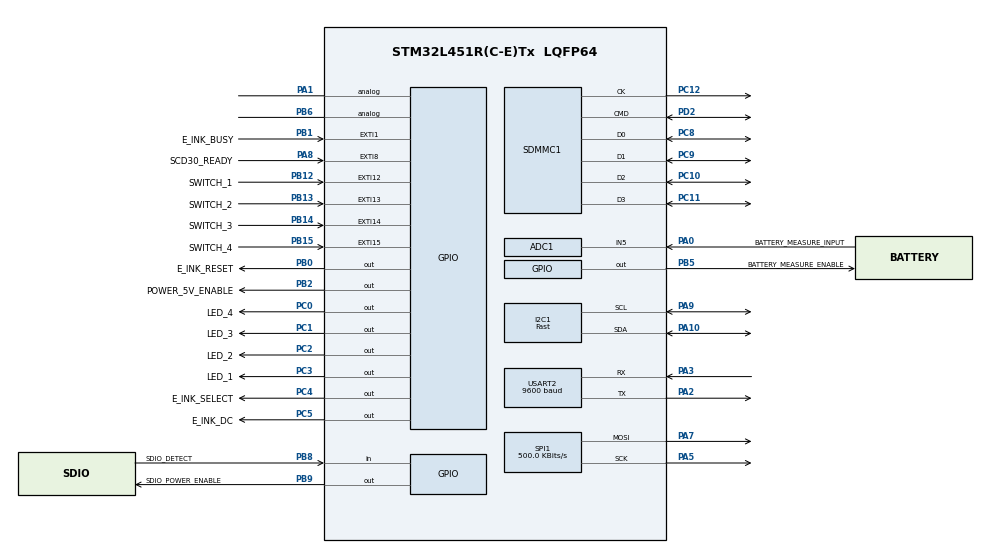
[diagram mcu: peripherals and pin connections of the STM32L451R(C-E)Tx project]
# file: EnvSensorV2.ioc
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ADC1.Channel-0\#ChannelRegularConversion=ADC_CHANNEL_5
ADC1.Channel-16\#ChannelRegularConversion=ADC_CHANNEL_5
ADC1.Channel-17\#ChannelRegularConversion=ADC_CHANNEL_5
ADC1.Channel-18\#ChannelRegularConversion=ADC_CHANNEL_5
ADC1.Channel-19\#ChannelRegularConversion=ADC_CHANNEL_5
ADC1.Channel-20\#ChannelRegularConversion=ADC_CHANNEL_5
ADC1.Channel-21\#ChannelRegularConversion=ADC_CHANNEL_5
ADC1.Channel-22\#ChannelRegularConversion=ADC_CHANNEL_5
ADC1.Channel-23\#ChannelRegularConversion=ADC_CHANNEL_5
ADC1.Channel-24\#ChannelRegularConversion=ADC_CHANNEL_5
ADC1.Channel-25\#ChannelRegularConversion=ADC_CHANNEL_5
ADC1.Channel-26\#ChannelRegularConversion=ADC_CHANNEL_5
ADC1.Channel-27\#ChannelRegularConversion=ADC_CHANNEL_5
ADC1.Channel-28\#ChannelRegularConversion=ADC_CHANNEL_5
ADC1.Channel-29\#ChannelRegularConversion=ADC_CHANNEL_5
ADC1.Channel-30\#ChannelRegularConversion=ADC_CHANNEL_5
ADC1.ClockPrescaler=ADC_CLOCK_ASYNC_DIV16
ADC1.NbrOfConversion=16
ADC1.NbrOfConversionFlag=1
ADC1.OffsetNumber-0\#ChannelRegularConversion=ADC_OFFSET_NONE
ADC1.OffsetNumber-16\#ChannelRegularConversion=ADC_OFFSET_NONE
ADC1.OffsetNumber-17\#ChannelRegularConversion=ADC_OFFSET_NONE
ADC1.OffsetNumber-18\#ChannelRegularConversion=ADC_OFFSET_NONE
ADC1.OffsetNumber-19\#ChannelRegularConversion=ADC_OFFSET_NONE
ADC1.OffsetNumber-20\#ChannelRegularConversion=ADC_OFFSET_NONE
ADC1.OffsetNumber-21\#ChannelRegularConversion=ADC_OFFSET_NONE
ADC1.OffsetNumber-22\#ChannelRegularConversion=ADC_OFFSET_NONE
ADC1.OffsetNumber-23\#ChannelRegularConversion=ADC_OFFSET_NONE
ADC1.OffsetNumber-24\#ChannelRegularConversion=ADC_OFFSET_NONE
ADC1.OffsetNumber-25\#ChannelRegularConversion=ADC_OFFSET_NONE
ADC1.OffsetNumber-26\#ChannelRegularConversion=ADC_OFFSET_NONE
ADC1.OffsetNumber-27\#ChannelRegularConversion=ADC_OFFSET_NONE
ADC1.OffsetNumber-28\#ChannelRegularConversion=ADC_OFFSET_NONE
ADC1.OffsetNumber-29\#ChannelRegularConversion=ADC_OFFSET_NONE
ADC1.OffsetNumber-30\#ChannelRegularConversion=ADC_OFFSET_NONE
ADC1.OversamplingMode=DISABLE
ADC1.Rank-0\#ChannelRegularConversion=1
ADC1.Rank-16\#ChannelRegularConversion=2
ADC1.Rank-17\#ChannelRegularConversion=3
ADC1.Rank-18\#ChannelRegularConversion=4
ADC1.Rank-19\#ChannelRegularConversion=5
ADC1.Rank-20\#ChannelRegularConversion=6
ADC1.Rank-21\#ChannelRegularConversion=7
ADC1.Rank-22\#ChannelRegularConversion=8
ADC1.Rank-23\#ChannelRegularConversion=9
ADC1.Rank-24\#ChannelRegularConversion=10
ADC1.Rank-25\#ChannelRegularConversion=11
ADC1.Rank-26\#ChannelRegularConversion=12
ADC1.Rank-27\#ChannelRegularConversion=13
ADC1.Rank-28\#ChannelRegularConversion=14
ADC1.Rank-29\#ChannelRegularConversion=15
ADC1.Rank-30\#ChannelRegularConversion=16
ADC1.SamplingTime-0\#ChannelRegularConversion=ADC_SAMPLETIME_640CYCLES_5
ADC1.SamplingTime-16\#ChannelRegularConversion=ADC_SAMPLETIME_2CYCLES_5
ADC1.SamplingTime-17\#ChannelRegularConversion=ADC_SAMPLETIME_2CYCLES_5
ADC1.SamplingTime-18\#ChannelRegularConversion=ADC_SAMPLETIME_2CYCLES_5
ADC1.SamplingTime-19\#ChannelRegularConversion=ADC_SAMPLETIME_2CYCLES_5
ADC1.SamplingTime-20\#ChannelRegularConversion=ADC_SAMPLETIME_2CYCLES_5
ADC1.SamplingTime-21\#ChannelRegularConversion=ADC_SAMPLETIME_2CYCLES_5
ADC1.SamplingTime-22\#ChannelRegularConversion=ADC_SAMPLETIME_2CYCLES_5
ADC1.SamplingTime-23\#ChannelRegularConversion=ADC_SAMPLETIME_2CYCLES_5
ADC1.SamplingTime-24\#ChannelRegularConversion=ADC_SAMPLETIME_2CYCLES_5
ADC1.SamplingTime-25\#ChannelRegularConversion=ADC_SAMPLETIME_2CYCLES_5
ADC1.SamplingTime-26\#ChannelRegularConversion=ADC_SAMPLETIME_2CYCLES_5
ADC1.SamplingTime-27\#ChannelRegularConversion=ADC_SAMPLETIME_2CYCLES_5
ADC1.SamplingTime-28\#ChannelRegularConversion=ADC_SAMPLETIME_2CYCLES_5
ADC1.SamplingTime-29\#ChannelRegularConversion=ADC_SAMPLETIME_2CYCLES_5
ADC1.SamplingTime-30\#ChannelRegularConversion=ADC_SAMPLETIME_2CYCLES_5
ADC1.master=1
FATFS.BSP.number=1
FATFS._CODE_PAGE=852
FATFS._MAX_SS=4096
FATFS._USE_LFN=3
FATFS0.BSP.STBoard=false
FATFS0.BSP.api=Unknown
FATFS0.BSP.instance=PB8
FATFS0.BSP.ip=GPIO
FATFS0.BSP.mode=Input
FATFS0.BSP.name=Detect_SDIO
FATFS0.BSP.solution=PB8
FREERTOS.HEAP_NUMBER=3
FREERTOS.INCLUDE_xTaskGetHandle=0
FREERTOS.Mutexes01=i2c1Mutex,Static,i2c1MutexControlBlock
FREERTOS.Queues01=debugLogQueue,16,30,1,Static,debugLogQueueBuffer,debugLogQueueControlBlock;sensorReadoutsQueue,6,ReadoutMessage_t,0,Static,sensorReadoutsQueueBuffer,sensorReadoutsQueueControlBlock;displayCommandsQueue,6,DisplayCommandMessage_t,0,Static,displayCommandsQueueBuffer,displayCommandsQueueControlBlock
FREERTOS.Tasks01=defaultTask,24,1024,StartDefaultTask,Default,NULL,Static,defaultTaskBuffer,defaultTaskControlBlock
FREERTOS.configCHECK_FOR_STACK_OVERFLOW=0
FREERTOS.configTOTAL_HEAP_SIZE=50000
FREERTOS.configUSE_NEWLIB_REENTRANT=1
I2C1.I2C_Speed_Mode=I2C_Fast
I2C1.Timing=0x00000004
Mcu.Family=STM32L4
Mcu.Name=STM32L451R(C-E)Tx
Mcu.Package=LQFP64
NVIC.EXTI15_10_IRQn=true\:5\:0\:false\:false\:true\:true\:true\:true\:true
NVIC.EXTI1_IRQn=true\:5\:0\:false\:false\:true\:true\:true\:true\:true
NVIC.EXTI9_5_IRQn=true\:5\:0\:true\:false\:true\:true\:true\:true\:true
NVIC.PriorityGroup=NVIC_PRIORITYGROUP_4
NVIC.SDMMC1_IRQn=true\:5\:0\:false\:false\:true\:true\:true\:true\:true
NVIC.TIM6_DAC_IRQn=true\:15\:0\:false\:false\:true\:false\:false\:true\:true
NVIC.TimeBase=TIM6_DAC_IRQn
NVIC.TimeBaseIP=TIM6
NVIC.USART2_IRQn=true\:5\:0\:false\:false\:true\:true\:true\:true\:true
PA0.GPIO_Label=BATTERY_MEASURE_INPUT
PA0.Signal=ADCx_IN5
PA1.Signal=GPIO_Analog
PA10.Mode=I2C
PA10.Signal=I2C1_SDA
PA13\ (JTMS/SWDIO).Mode=Trace_Asynchronous_SW
PA13\ (JTMS/SWDIO).Signal=SYS_JTMS-SWDIO
PA14\ (JTCK/SWCLK).Mode=Trace_Asynchronous_SW
PA14\ (JTCK/SWCLK).Signal=SYS_JTCK-SWCLK
PA2.Mode=Asynchronous
PA2.Signal=USART2_TX
PA3.Mode=Asynchronous
PA3.Signal=USART2_RX
PA5.Mode=TX_Only_Simplex_Unidirect_Master
PA5.Signal=SPI1_SCK
PA7.Mode=TX_Only_Simplex_Unidirect_Master
PA7.Signal=SPI1_MOSI
PA8.GPIO_Label=SCD30_READY
PA8.GPIO_PuPd=GPIO_NOPULL
PA8.Signal=GPXTI8
PA9.Mode=I2C
PA9.Signal=I2C1_SCL
PB0.GPIO_Label=E_INK_RESET
PB0.Signal=GPIO_Output
PB1.GPIO_Label=E_INK_BUSY
PB1.Signal=GPXTI1
PB12.GPIO_Label=SWITCH_1
PB12.Signal=GPXTI12
PB13.GPIO_Label=SWITCH_2
PB13.Signal=GPXTI13
PB14.GPIO_Label=SWITCH_3
PB14.Signal=GPXTI14
PB15.GPIO_Label=SWITCH_4
PB15.Signal=GPXTI15
PB2.GPIO_Label=POWER_5V_ENABLE
PB2.PinState=GPIO_PIN_SET
PB2.Signal=GPIO_Output
PB3\ (JTDO/TRACESWO).Mode=Trace_Asynchronous_SW
PB3\ (JTDO/TRACESWO).Signal=SYS_JTDO-SWO
PB5.GPIO_Label=BATTERY_MEASURE_ENABLE
PB5.Signal=GPIO_Output
PB6.Signal=GPIO_Analog
PB8.GPIO_Label=SDIO_DETECT
PB8.Signal=GPIO_Input
PB9.GPIO_Label=SDIO_POWER_ENABLE
PB9.Signal=GPIO_Output
PC0.GPIO_Label=LED_4
PC0.Signal=GPIO_Output
PC1.GPIO_Label=LED_3
PC1.Signal=GPIO_Output
PC10.Mode=SD_4_bits_Wide_bus
PC10.Signal=SDMMC1_D2
PC11.Mode=SD_4_bits_Wide_bus
PC11.Signal=SDMMC1_D3
PC12.Mode=SD_4_bits_Wide_bus
PC12.Signal=SDMMC1_CK
PC2.GPIO_Label=LED_2
PC2.Signal=GPIO_Output
PC3.GPIO_Label=LED_1
PC3.Signal=GPIO_Output
PC4.GPIO_Label=E_INK_SELECT
PC4.Signal=GPIO_Output
PC5.GPIO_Label=E_INK_DC
PC5.GPIO_Speed=GPIO_SPEED_FREQ_HIGH
PC5.Signal=GPIO_Output
PC8.Mode=SD_4_bits_Wide_bus
PC8.Signal=SDMMC1_D0
PC9.Mode=SD_4_bits_Wide_bus
PC9.Signal=SDMMC1_D1
PD2.Mode=SD_4_bits_Wide_bus
PD2.Signal=SDMMC1_CMD
PH0-OSC_IN\ (PH0).Mode=HSE-External-Oscillator
PH0-OSC_IN\ (PH0).Signal=RCC_OSC_IN
PH1-OSC_OUT\ (PH1).Mode=HSE-External-Oscillator
PH1-OSC_OUT\ (PH1).Signal=RCC_OSC_OUT
ProjectManager.HeapSize=0x200
ProjectManager.StackSize=0x400
ProjectManager.TargetToolchain=STM32CubeIDE
RCC.ADCFreq_Value=64000000
RCC.HSE_VALUE=16000000
RCC.HSI48_VALUE=48000000
RCC.HSI_VALUE=16000000
RCC.LSE_VALUE=32768
RCC.MSI_VALUE=4000000
RCC.PLLSAI1Q=RCC_PLLQ_DIV4
RCC.PLLSourceVirtual=RCC_PLLSOURCE_HSE
RCC.VCOOutputFreq_Value=128000000
SH.ADCx_IN5.0=ADC1_IN5,IN5-Single-Ended
SPI1.BaudRatePrescaler=SPI_BAUDRATEPRESCALER_8
SPI1.CalculateBaudRate=500.0 KBits/s
SPI1.DataSize=SPI_DATASIZE_8BIT
SPI1.Direction=SPI_DIRECTION_2LINES
SPI1.Mode=SPI_MODE_MASTER
SPI1.VirtualType=VM_MASTER
USART2.BaudRate=9600
USART2.VirtualMode-Asynchronous=VM_ASYNC
VP_CRC_VS_CRC.Mode=CRC_Activate
VP_FATFS_VS_SDIO.Mode=SDIO
VP_FREERTOS_VS_CMSIS_V2.Mode=CMSIS_V2
VP_RTC_VS_RTC_Activate.Mode=RTC_Enabled
VP_SYS_VS_tim6.Mode=TIM6
board=custom

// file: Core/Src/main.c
/* USER CODE BEGIN Header */
/**
  ******************************************************************************
  * @file           : main.c
  * @brief          : Main program body
  ******************************************************************************
  * @attention
  *
  * <h2><center>&copy; Copyright (c) 2022 STMicroelectronics.
  * All rights reserved.</center></h2>
  *
  * This software component is licensed by ST under BSD 3-Clause license,
  * the "License"; You may not use this file except in compliance with the
  * License. You may obtain a copy of the License at:
  *                        opensource.org/licenses/BSD-3-Clause
  *
  ******************************************************************************
  */
/* USER CODE END Header */
#include "main.h"
#include "cmsis_os.h"
#include "fatfs.h"
#include "app_touchgfx.h"

/* USER CODE BEGIN Includes */
#include <EnvSensorV2.hpp>
#include <Readouts/SensorMessages.hpp>
#include <Display/DisplayCommandMessage.hpp>
/* USER CODE END Includes */

typedef StaticTask_t osStaticThreadDef_t;
typedef StaticQueue_t osStaticMessageQDef_t;
typedef StaticSemaphore_t osStaticMutexDef_t;

ADC_HandleTypeDef hadc1;

CRC_HandleTypeDef hcrc;

I2C_HandleTypeDef hi2c1;

RTC_HandleTypeDef hrtc;

SD_HandleTypeDef hsd1;

SPI_HandleTypeDef hspi1;

UART_HandleTypeDef huart2;

/* Definitions for defaultTask */
osThreadId_t defaultTaskHandle;
uint32_t defaultTaskBuffer[ 1024 ];
osStaticThreadDef_t defaultTaskControlBlock;
const osThreadAttr_t defaultTask_attributes = {
  .name = "defaultTask",
  .cb_mem = &defaultTaskControlBlock,
  .cb_size = sizeof(defaultTaskControlBlock),
  .stack_mem = &defaultTaskBuffer[0],
  .stack_size = sizeof(defaultTaskBuffer),
  .priority = (osPriority_t) osPriorityNormal,
};
/* Definitions for debugLogQueue */
osMessageQueueId_t debugLogQueueHandle;
uint8_t debugLogQueueBuffer[ 16 * 30 ];
osStaticMessageQDef_t debugLogQueueControlBlock;
const osMessageQueueAttr_t debugLogQueue_attributes = {
  .name = "debugLogQueue",
  .cb_mem = &debugLogQueueControlBlock,
  .cb_size = sizeof(debugLogQueueControlBlock),
  .mq_mem = &debugLogQueueBuffer,
  .mq_size = sizeof(debugLogQueueBuffer)
};
/* Definitions for sensorReadoutsQueue */
osMessageQueueId_t sensorReadoutsQueueHandle;
uint8_t sensorReadoutsQueueBuffer[ 6 * sizeof( ReadoutMessage_t ) ];
osStaticMessageQDef_t sensorReadoutsQueueControlBlock;
const osMessageQueueAttr_t sensorReadoutsQueue_attributes = {
  .name = "sensorReadoutsQueue",
  .cb_mem = &sensorReadoutsQueueControlBlock,
  .cb_size = sizeof(sensorReadoutsQueueControlBlock),
  .mq_mem = &sensorReadoutsQueueBuffer,
  .mq_size = sizeof(sensorReadoutsQueueBuffer)
};
/* Definitions for displayCommandsQueue */
osMessageQueueId_t displayCommandsQueueHandle;
uint8_t displayCommandsQueueBuffer[ 6 * sizeof( DisplayCommandMessage_t ) ];
osStaticMessageQDef_t displayCommandsQueueControlBlock;
const osMessageQueueAttr_t displayCommandsQueue_attributes = {
  .name = "displayCommandsQueue",
  .cb_mem = &displayCommandsQueueControlBlock,
  .cb_size = sizeof(displayCommandsQueueControlBlock),
  .mq_mem = &displayCommandsQueueBuffer,
  .mq_size = sizeof(displayCommandsQueueBuffer)
};
/* Definitions for i2c1Mutex */
osMutexId_t i2c1MutexHandle;
osStaticMutexDef_t i2c1MutexControlBlock;
const osMutexAttr_t i2c1Mutex_attributes = {
  .name = "i2c1Mutex",
  .cb_mem = &i2c1MutexControlBlock,
  .cb_size = sizeof(i2c1MutexControlBlock),
};

void SystemClock_Config(void);
void PeriphCommonClock_Config(void);
static void MX_GPIO_Init(void);
static void MX_I2C1_Init(void);
static void MX_USART2_UART_Init(void);
static void MX_SPI1_Init(void);
static void MX_CRC_Init(void);
static void MX_ADC1_Init(void);
static void MX_RTC_Init(void);
static void MX_SDMMC1_SD_Init(void);
void StartDefaultTask(void *argument);

int main(void)
{

  /* MCU Configuration--------------------------------------------------------*/

  /* Reset of all peripherals, Initializes the Flash interface and the Systick. */
  HAL_Init();

  /* Configure the system clock */
  SystemClock_Config();

/* Configure the peripherals common clocks */
  PeriphCommonClock_Config();

  /* Initialize all configured peripherals */
  MX_GPIO_Init();
  MX_I2C1_Init();
  MX_USART2_UART_Init();
  MX_SPI1_Init();
  MX_CRC_Init();
  MX_ADC1_Init();
  MX_RTC_Init();
  MX_SDMMC1_SD_Init();
  MX_FATFS_Init();
  MX_TouchGFX_Init();
  /* Call PreOsInit function */
  MX_TouchGFX_PreOSInit();
  /* USER CODE BEGIN 2 */
  HAL_GPIO_WritePin(LED_2_GPIO_Port, LED_2_Pin, GPIO_PIN_SET);
  /* USER CODE END 2 */

  /* Init scheduler */
  osKernelInitialize();
  /* Create the mutex(es) */
  /* creation of i2c1Mutex */
  i2c1MutexHandle = osMutexNew(&i2c1Mutex_attributes);

  /* Create the queue(s) */
  /* creation of debugLogQueue */
  debugLogQueueHandle = osMessageQueueNew (16, 30, &debugLogQueue_attributes);

  /* creation of sensorReadoutsQueue */
  sensorReadoutsQueueHandle = osMessageQueueNew (6, sizeof(ReadoutMessage_t), &sensorReadoutsQueue_attributes);

  /* creation of displayCommandsQueue */
  displayCommandsQueueHandle = osMessageQueueNew (6, sizeof(DisplayCommandMessage_t), &displayCommandsQueue_attributes);

  /* Create the thread(s) */
  /* creation of defaultTask */
  defaultTaskHandle = osThreadNew(StartDefaultTask, NULL, &defaultTask_attributes);

  /* USER CODE BEGIN RTOS_THREADS */
  EnvSensorV2_Init();
  /* add threads, ... */
  /* USER CODE END RTOS_THREADS */

  /* Start scheduler */
  osKernelStart();
  /* We should never get here as control is now taken by the scheduler */
  /* Infinite loop */
  while (1)
  {

    /* USER CODE BEGIN 3 */
	  HAL_GPIO_TogglePin(LED_2_GPIO_Port, LED_2_Pin);
	  HAL_Delay(250);
  }
  /* USER CODE END 3 */
}

void SystemClock_Config(void)
{
  RCC_OscInitTypeDef RCC_OscInitStruct = {0};
  RCC_ClkInitTypeDef RCC_ClkInitStruct = {0};

  /** Configure the main internal regulator output voltage
  */
  if (HAL_PWREx_ControlVoltageScaling(PWR_REGULATOR_VOLTAGE_SCALE1) != HAL_OK)
  {
    Error_Handler();
  }

  /** Initializes the RCC Oscillators according to the specified parameters
  * in the RCC_OscInitTypeDef structure.
  */
  RCC_OscInitStruct.OscillatorType = RCC_OSCILLATORTYPE_LSI|RCC_OSCILLATORTYPE_HSE
                              |RCC_OSCILLATORTYPE_MSI;
  RCC_OscInitStruct.HSEState = RCC_HSE_ON;
  RCC_OscInitStruct.LSIState = RCC_LSI_ON;
  RCC_OscInitStruct.MSIState = RCC_MSI_ON;
  RCC_OscInitStruct.MSICalibrationValue = 0;
  RCC_OscInitStruct.MSIClockRange = RCC_MSIRANGE_6;
  RCC_OscInitStruct.PLL.PLLState = RCC_PLL_NONE;
  if (HAL_RCC_OscConfig(&RCC_OscInitStruct) != HAL_OK)
  {
    Error_Handler();
  }

  /** Initializes the CPU, AHB and APB buses clocks
  */
  RCC_ClkInitStruct.ClockType = RCC_CLOCKTYPE_HCLK|RCC_CLOCKTYPE_SYSCLK
                              |RCC_CLOCKTYPE_PCLK1|RCC_CLOCKTYPE_PCLK2;
  RCC_ClkInitStruct.SYSCLKSource = RCC_SYSCLKSOURCE_MSI;
  RCC_ClkInitStruct.AHBCLKDivider = RCC_SYSCLK_DIV1;
  RCC_ClkInitStruct.APB1CLKDivider = RCC_HCLK_DIV1;
  RCC_ClkInitStruct.APB2CLKDivider = RCC_HCLK_DIV1;

  if (HAL_RCC_ClockConfig(&RCC_ClkInitStruct, FLASH_LATENCY_0) != HAL_OK)
  {
    Error_Handler();
  }
}

void PeriphCommonClock_Config(void)
{
  RCC_PeriphCLKInitTypeDef PeriphClkInit = {0};

  /** Initializes the peripherals clock
  */
  PeriphClkInit.PeriphClockSelection = RCC_PERIPHCLK_SDMMC1|RCC_PERIPHCLK_ADC;
  PeriphClkInit.AdcClockSelection = RCC_ADCCLKSOURCE_PLLSAI1;
  PeriphClkInit.Sdmmc1ClockSelection = RCC_SDMMC1CLKSOURCE_PLLSAI1;
  PeriphClkInit.PLLSAI1.PLLSAI1Source = RCC_PLLSOURCE_HSE;
  PeriphClkInit.PLLSAI1.PLLSAI1M = 1;
  PeriphClkInit.PLLSAI1.PLLSAI1N = 8;
  PeriphClkInit.PLLSAI1.PLLSAI1P = RCC_PLLP_DIV7;
  PeriphClkInit.PLLSAI1.PLLSAI1Q = RCC_PLLQ_DIV4;
  PeriphClkInit.PLLSAI1.PLLSAI1R = RCC_PLLR_DIV2;
  PeriphClkInit.PLLSAI1.PLLSAI1ClockOut = RCC_PLLSAI1_48M2CLK|RCC_PLLSAI1_ADC1CLK;
  if (HAL_RCCEx_PeriphCLKConfig(&PeriphClkInit) != HAL_OK)
  {
    Error_Handler();
  }
}

static void MX_ADC1_Init(void)
{

  ADC_ChannelConfTypeDef sConfig = {0};

  /** Common config
  */
  hadc1.Instance = ADC1;
  hadc1.Init.ClockPrescaler = ADC_CLOCK_ASYNC_DIV16;
  hadc1.Init.Resolution = ADC_RESOLUTION_12B;
  hadc1.Init.DataAlign = ADC_DATAALIGN_RIGHT;
  hadc1.Init.ScanConvMode = ADC_SCAN_ENABLE;
  hadc1.Init.EOCSelection = ADC_EOC_SINGLE_CONV;
  hadc1.Init.LowPowerAutoWait = DISABLE;
  hadc1.Init.ContinuousConvMode = DISABLE;
  hadc1.Init.NbrOfConversion = 16;
  hadc1.Init.DiscontinuousConvMode = DISABLE;
  hadc1.Init.ExternalTrigConv = ADC_SOFTWARE_START;
  hadc1.Init.ExternalTrigConvEdge = ADC_EXTERNALTRIGCONVEDGE_NONE;
  hadc1.Init.DMAContinuousRequests = DISABLE;
  hadc1.Init.Overrun = ADC_OVR_DATA_PRESERVED;
  hadc1.Init.OversamplingMode = DISABLE;
  hadc1.Init.DFSDMConfig = ADC_DFSDM_MODE_ENABLE;
  if (HAL_ADC_Init(&hadc1) != HAL_OK)
  {
    Error_Handler();
  }

  /** Configure Regular Channel
  */
  sConfig.Channel = ADC_CHANNEL_5;
  sConfig.Rank = ADC_REGULAR_RANK_1;
  sConfig.SamplingTime = ADC_SAMPLETIME_640CYCLES_5;
  sConfig.SingleDiff = ADC_SINGLE_ENDED;
  sConfig.OffsetNumber = ADC_OFFSET_NONE;
  sConfig.Offset = 0;
  if (HAL_ADC_ConfigChannel(&hadc1, &sConfig) != HAL_OK)
  {
    Error_Handler();
  }

  /** Configure Regular Channel
  */
  sConfig.Rank = ADC_REGULAR_RANK_2;
  sConfig.SamplingTime = ADC_SAMPLETIME_2CYCLES_5;
  if (HAL_ADC_ConfigChannel(&hadc1, &sConfig) != HAL_OK)
  {
    Error_Handler();
  }

  /** Configure Regular Channel
  */
  sConfig.Rank = ADC_REGULAR_RANK_3;
  if (HAL_ADC_ConfigChannel(&hadc1, &sConfig) != HAL_OK)
  {
    Error_Handler();
  }

  /** Configure Regular Channel
  */
  sConfig.Rank = ADC_REGULAR_RANK_4;
  if (HAL_ADC_ConfigChannel(&hadc1, &sConfig) != HAL_OK)
  {
    Error_Handler();
  }

  /** Configure Regular Channel
  */
  sConfig.Rank = ADC_REGULAR_RANK_5;
  if (HAL_ADC_ConfigChannel(&hadc1, &sConfig) != HAL_OK)
  {
    Error_Handler();
  }

  /** Configure Regular Channel
  */
  sConfig.Rank = ADC_REGULAR_RANK_6;
  if (HAL_ADC_ConfigChannel(&hadc1, &sConfig) != HAL_OK)
  {
    Error_Handler();
  }

  /** Configure Regular Channel
  */
  sConfig.Rank = ADC_REGULAR_RANK_7;
  if (HAL_ADC_ConfigChannel(&hadc1, &sConfig) != HAL_OK)
  {
    Error_Handler();
  }

  /** Configure Regular Channel
  */
  sConfig.Rank = ADC_REGULAR_RANK_8;
  if (HAL_ADC_ConfigChannel(&hadc1, &sConfig) != HAL_OK)
  {
    Error_Handler();
  }

  /** Configure Regular Channel
  */
  sConfig.Rank = ADC_REGULAR_RANK_9;
  if (HAL_ADC_ConfigChannel(&hadc1, &sConfig) != HAL_OK)
  {
    Error_Handler();
  }

  /** Configure Regular Channel
  */
  sConfig.Rank = ADC_REGULAR_RANK_10;
  if (HAL_ADC_ConfigChannel(&hadc1, &sConfig) != HAL_OK)
  {
    Error_Handler();
  }

  /** Configure Regular Channel
  */
  sConfig.Rank = ADC_REGULAR_RANK_11;
  if (HAL_ADC_ConfigChannel(&hadc1, &sConfig) != HAL_OK)
  {
    Error_Handler();
  }

  /** Configure Regular Channel
  */
  sConfig.Rank = ADC_REGULAR_RANK_12;
  if (HAL_ADC_ConfigChannel(&hadc1, &sConfig) != HAL_OK)
  {
    Error_Handler();
  }

  /** Configure Regular Channel
  */
  sConfig.Rank = ADC_REGULAR_RANK_13;
  if (HAL_ADC_ConfigChannel(&hadc1, &sConfig) != HAL_OK)
  {
    Error_Handler();
  }

  /** Configure Regular Channel
  */
  sConfig.Rank = ADC_REGULAR_RANK_14;
  if (HAL_ADC_ConfigChannel(&hadc1, &sConfig) != HAL_OK)
  {
    Error_Handler();
  }

  /** Configure Regular Channel
  */
  sConfig.Rank = ADC_REGULAR_RANK_15;
  if (HAL_ADC_ConfigChannel(&hadc1, &sConfig) != HAL_OK)
  {
    Error_Handler();
  }

  /** Configure Regular Channel
  */
  sConfig.Rank = ADC_REGULAR_RANK_16;
  if (HAL_ADC_ConfigChannel(&hadc1, &sConfig) != HAL_OK)
  {
    Error_Handler();
  }

}

static void MX_CRC_Init(void)
{

  hcrc.Instance = CRC;
  hcrc.Init.DefaultPolynomialUse = DEFAULT_POLYNOMIAL_ENABLE;
  hcrc.Init.DefaultInitValueUse = DEFAULT_INIT_VALUE_ENABLE;
  hcrc.Init.InputDataInversionMode = CRC_INPUTDATA_INVERSION_NONE;
  hcrc.Init.OutputDataInversionMode = CRC_OUTPUTDATA_INVERSION_DISABLE;
  hcrc.InputDataFormat = CRC_INPUTDATA_FORMAT_BYTES;
  if (HAL_CRC_Init(&hcrc) != HAL_OK)
  {
    Error_Handler();
  }

}

static void MX_I2C1_Init(void)
{

  hi2c1.Instance = I2C1;
  hi2c1.Init.Timing = 0x00000004;
  hi2c1.Init.OwnAddress1 = 0;
  hi2c1.Init.AddressingMode = I2C_ADDRESSINGMODE_7BIT;
  hi2c1.Init.DualAddressMode = I2C_DUALADDRESS_DISABLE;
  hi2c1.Init.OwnAddress2 = 0;
  hi2c1.Init.OwnAddress2Masks = I2C_OA2_NOMASK;
  hi2c1.Init.GeneralCallMode = I2C_GENERALCALL_DISABLE;
  hi2c1.Init.NoStretchMode = I2C_NOSTRETCH_DISABLE;
  if (HAL_I2C_Init(&hi2c1) != HAL_OK)
  {
    Error_Handler();
  }

  /** Configure Analogue filter
  */
  if (HAL_I2CEx_ConfigAnalogFilter(&hi2c1, I2C_ANALOGFILTER_ENABLE) != HAL_OK)
  {
    Error_Handler();
  }

  /** Configure Digital filter
  */
  if (HAL_I2CEx_ConfigDigitalFilter(&hi2c1, 0) != HAL_OK)
  {
    Error_Handler();
  }

}

static void MX_RTC_Init(void)
{

  /** Initialize RTC Only
  */
  hrtc.Instance = RTC;
  hrtc.Init.HourFormat = RTC_HOURFORMAT_24;
  hrtc.Init.AsynchPrediv = 127;
  hrtc.Init.SynchPrediv = 255;
  hrtc.Init.OutPut = RTC_OUTPUT_DISABLE;
  hrtc.Init.OutPutRemap = RTC_OUTPUT_REMAP_NONE;
  hrtc.Init.OutPutPolarity = RTC_OUTPUT_POLARITY_HIGH;
  hrtc.Init.OutPutType = RTC_OUTPUT_TYPE_OPENDRAIN;
  if (HAL_RTC_Init(&hrtc) != HAL_OK)
  {
    Error_Handler();
  }

}

static void MX_SDMMC1_SD_Init(void)
{

  hsd1.Instance = SDMMC1;
  hsd1.Init.ClockEdge = SDMMC_CLOCK_EDGE_RISING;
  hsd1.Init.ClockBypass = SDMMC_CLOCK_BYPASS_DISABLE;
  hsd1.Init.ClockPowerSave = SDMMC_CLOCK_POWER_SAVE_DISABLE;
  hsd1.Init.BusWide = SDMMC_BUS_WIDE_4B;
  hsd1.Init.HardwareFlowControl = SDMMC_HARDWARE_FLOW_CONTROL_DISABLE;
  hsd1.Init.ClockDiv = 0;

}

static void MX_SPI1_Init(void)
{

  /* SPI1 parameter configuration*/
  hspi1.Instance = SPI1;
  hspi1.Init.Mode = SPI_MODE_MASTER;
  hspi1.Init.Direction = SPI_DIRECTION_2LINES;
  hspi1.Init.DataSize = SPI_DATASIZE_8BIT;
  hspi1.Init.CLKPolarity = SPI_POLARITY_LOW;
  hspi1.Init.CLKPhase = SPI_PHASE_1EDGE;
  hspi1.Init.NSS = SPI_NSS_SOFT;
  hspi1.Init.BaudRatePrescaler = SPI_BAUDRATEPRESCALER_8;
  hspi1.Init.FirstBit = SPI_FIRSTBIT_MSB;
  hspi1.Init.TIMode = SPI_TIMODE_DISABLE;
  hspi1.Init.CRCCalculation = SPI_CRCCALCULATION_DISABLE;
  hspi1.Init.CRCPolynomial = 7;
  hspi1.Init.CRCLength = SPI_CRC_LENGTH_DATASIZE;
  hspi1.Init.NSSPMode = SPI_NSS_PULSE_ENABLE;
  if (HAL_SPI_Init(&hspi1) != HAL_OK)
  {
    Error_Handler();
  }

}

static void MX_USART2_UART_Init(void)
{

  huart2.Instance = USART2;
  huart2.Init.BaudRate = 9600;
  huart2.Init.WordLength = UART_WORDLENGTH_8B;
  huart2.Init.StopBits = UART_STOPBITS_1;
  huart2.Init.Parity = UART_PARITY_NONE;
  huart2.Init.Mode = UART_MODE_TX_RX;
  huart2.Init.HwFlowCtl = UART_HWCONTROL_NONE;
  huart2.Init.OverSampling = UART_OVERSAMPLING_16;
  huart2.Init.OneBitSampling = UART_ONE_BIT_SAMPLE_DISABLE;
  huart2.AdvancedInit.AdvFeatureInit = UART_ADVFEATURE_NO_INIT;
  if (HAL_UART_Init(&huart2) != HAL_OK)
  {
    Error_Handler();
  }

}

static void MX_GPIO_Init(void)
{
  GPIO_InitTypeDef GPIO_InitStruct = {0};

  /* GPIO Ports Clock Enable */
  __HAL_RCC_GPIOH_CLK_ENABLE();
  __HAL_RCC_GPIOC_CLK_ENABLE();
  __HAL_RCC_GPIOA_CLK_ENABLE();
  __HAL_RCC_GPIOB_CLK_ENABLE();
  __HAL_RCC_GPIOD_CLK_ENABLE();

  /*Configure GPIO pin Output Level */
  HAL_GPIO_WritePin(GPIOC, LED_4_Pin|LED_3_Pin|LED_2_Pin|LED_1_Pin
                          |E_INK_SELECT_Pin|E_INK_DC_Pin, GPIO_PIN_RESET);

  /*Configure GPIO pin Output Level */
  HAL_GPIO_WritePin(GPIOB, E_INK_RESET_Pin|BATTERY_MEASURE_ENABLE_Pin|SDIO_POWER_ENABLE_Pin, GPIO_PIN_RESET);

  /*Configure GPIO pin Output Level */
  HAL_GPIO_WritePin(POWER_5V_ENABLE_GPIO_Port, POWER_5V_ENABLE_Pin, GPIO_PIN_SET);

  /*Configure GPIO pins : LED_4_Pin LED_3_Pin LED_2_Pin LED_1_Pin
                           E_INK_SELECT_Pin */
  GPIO_InitStruct.Pin = LED_4_Pin|LED_3_Pin|LED_2_Pin|LED_1_Pin
                          |E_INK_SELECT_Pin;
  GPIO_InitStruct.Mode = GPIO_MODE_OUTPUT_PP;
  GPIO_InitStruct.Pull = GPIO_NOPULL;
  GPIO_InitStruct.Speed = GPIO_SPEED_FREQ_LOW;
  HAL_GPIO_Init(GPIOC, &GPIO_InitStruct);

  /*Configure GPIO pin : PA1 */
  GPIO_InitStruct.Pin = GPIO_PIN_1;
  GPIO_InitStruct.Mode = GPIO_MODE_ANALOG;
  GPIO_InitStruct.Pull = GPIO_NOPULL;
  HAL_GPIO_Init(GPIOA, &GPIO_InitStruct);

  /*Configure GPIO pin : E_INK_DC_Pin */
  GPIO_InitStruct.Pin = E_INK_DC_Pin;
  GPIO_InitStruct.Mode = GPIO_MODE_OUTPUT_PP;
  GPIO_InitStruct.Pull = GPIO_NOPULL;
  GPIO_InitStruct.Speed = GPIO_SPEED_FREQ_HIGH;
  HAL_GPIO_Init(E_INK_DC_GPIO_Port, &GPIO_InitStruct);

  /*Configure GPIO pins : E_INK_RESET_Pin POWER_5V_ENABLE_Pin BATTERY_MEASURE_ENABLE_Pin SDIO_POWER_ENABLE_Pin */
  GPIO_InitStruct.Pin = E_INK_RESET_Pin|POWER_5V_ENABLE_Pin|BATTERY_MEASURE_ENABLE_Pin|SDIO_POWER_ENABLE_Pin;
  GPIO_InitStruct.Mode = GPIO_MODE_OUTPUT_PP;
  GPIO_InitStruct.Pull = GPIO_NOPULL;
  GPIO_InitStruct.Speed = GPIO_SPEED_FREQ_LOW;
  HAL_GPIO_Init(GPIOB, &GPIO_InitStruct);

  /*Configure GPIO pins : E_INK_BUSY_Pin SWITCH_1_Pin SWITCH_2_Pin SWITCH_3_Pin
                           SWITCH_4_Pin */
  GPIO_InitStruct.Pin = E_INK_BUSY_Pin|SWITCH_1_Pin|SWITCH_2_Pin|SWITCH_3_Pin
                          |SWITCH_4_Pin;
  GPIO_InitStruct.Mode = GPIO_MODE_IT_RISING;
  GPIO_InitStruct.Pull = GPIO_NOPULL;
  HAL_GPIO_Init(GPIOB, &GPIO_InitStruct);

  /*Configure GPIO pin : SCD30_READY_Pin */
  GPIO_InitStruct.Pin = SCD30_READY_Pin;
  GPIO_InitStruct.Mode = GPIO_MODE_IT_RISING;
  GPIO_InitStruct.Pull = GPIO_NOPULL;
  HAL_GPIO_Init(SCD30_READY_GPIO_Port, &GPIO_InitStruct);

  /*Configure GPIO pin : PB6 */
  GPIO_InitStruct.Pin = GPIO_PIN_6;
  GPIO_InitStruct.Mode = GPIO_MODE_ANALOG;
  GPIO_InitStruct.Pull = GPIO_NOPULL;
  HAL_GPIO_Init(GPIOB, &GPIO_InitStruct);

  /*Configure GPIO pin : SDIO_DETECT_Pin */
  GPIO_InitStruct.Pin = SDIO_DETECT_Pin;
  GPIO_InitStruct.Mode = GPIO_MODE_INPUT;
  GPIO_InitStruct.Pull = GPIO_NOPULL;
  HAL_GPIO_Init(SDIO_DETECT_GPIO_Port, &GPIO_InitStruct);

  /* EXTI interrupt init*/
  HAL_NVIC_SetPriority(EXTI1_IRQn, 5, 0);
  HAL_NVIC_EnableIRQ(EXTI1_IRQn);

  HAL_NVIC_SetPriority(EXTI9_5_IRQn, 5, 0);
  HAL_NVIC_EnableIRQ(EXTI9_5_IRQn);

  HAL_NVIC_SetPriority(EXTI15_10_IRQn, 5, 0);
  HAL_NVIC_EnableIRQ(EXTI15_10_IRQn);

}

void StartDefaultTask(void *argument)
{
  /* USER CODE BEGIN 5 */
//	for (;;) {
//		osDelay(1000 / portTICK_RATE_MS);
//	}
  MX_TouchGFX_Process();
  /* USER CODE END 5 */
}

void HAL_TIM_PeriodElapsedCallback(TIM_HandleTypeDef *htim)
{
  if (htim->Instance == TIM6) {
    HAL_IncTick();
  }
}

void Error_Handler(void)
{
  /* USER CODE BEGIN Error_Handler_Debug */
  /* User can add his own implementation to report the HAL error return state */
  __disable_irq();
  HAL_GPIO_WritePin(LED_4_GPIO_Port, LED_4_Pin, GPIO_PIN_SET);
  while (1)
  {
  }
  /* USER CODE END Error_Handler_Debug */
}
